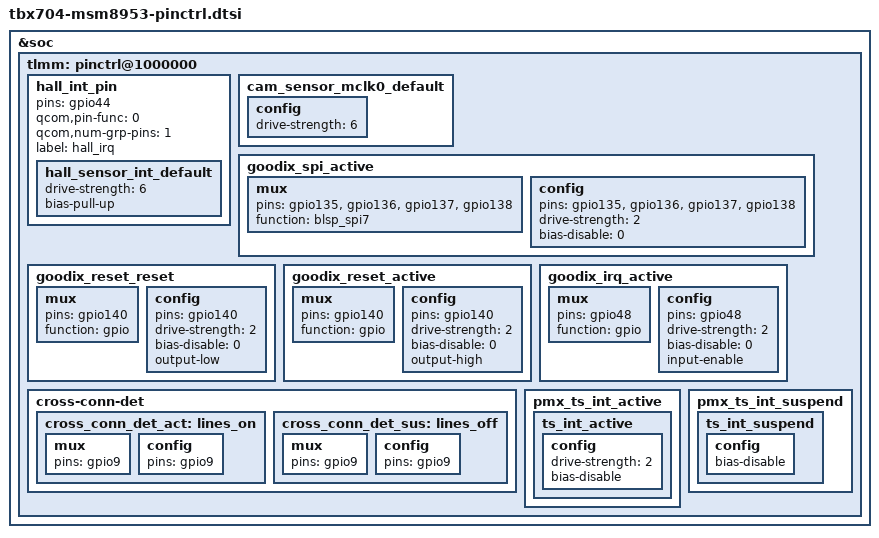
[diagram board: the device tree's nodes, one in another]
/*
 * Copyright (c) 2015-2016, The Linux Foundation. All rights reserved.
 *
 * This program is free software; you can redistribute it and/or modify
 * it under the terms of the GNU General Public License version 2 and
 * only version 2 as published by the Free Software Foundation.
 *
 * This program is distributed in the hope that it will be useful,
 * but WITHOUT ANY WARRANTY; without even the implied warranty of
 * MERCHANTABILITY or FITNESS FOR A PARTICULAR PURPOSE.  See the
 * GNU General Public License for more details.
 */

&soc {
	tlmm: pinctrl@1000000 {
		hall_int_pin {
			pins = "gpio44";
			qcom,pin-func = <0>;
			qcom,num-grp-pins = <1>;
			label = "hall_irq";
			hall_sensor_int_default: hall_sensor_int_default {
				drive-strength = <6>;
				bias-pull-up;
			};
		};
		/*sensors */
		cam_sensor_mclk0_default: cam_sensor_mclk0_default {
			config {
				drive-strength = <6>; /* 6 MA */
			};
		};
		goodix_spi_active: goodix_spi_active{
			mux {
				pins = "gpio135", "gpio136", "gpio137", "gpio138";
				function = "blsp_spi7";
			};
			config {
				pins = "gpio135", "gpio136", "gpio137", "gpio138";
				drive-strength = <2>;
				bias-disable = <0>;
			};
		};
		goodix_reset_reset: goodix_reset_reset{
			mux {
				pins = "gpio140";
				function = "gpio";
			};
			config {
				pins = "gpio140";
				drive-strength = <2>;
				bias-disable = <0>;
				output-low;
			};
		};
		goodix_reset_active: goodix_reset_active{
			mux {
				pins = "gpio140";
				function = "gpio";
			};
			config {
				pins = "gpio140";
				drive-strength = <2>;
				bias-disable = <0>;
				output-high;
			};
		};
		goodix_irq_active: goodix_irq_active {
			mux {
				pins = "gpio48";
				function = "gpio";
			};
			config {
				pins = "gpio48";
				drive-strength = <2>;
				bias-disable = <0>;
				input-enable;
			};
		};
		cross-conn-det {
			cross_conn_det_act: lines_on {
				mux {
					pins = "gpio9";
				};

				config {
					pins = "gpio9";
				};
			};

			cross_conn_det_sus: lines_off {
				mux {
					pins = "gpio9";
				};

				config {
					pins = "gpio9";
				};
			};
		};
		/* add pingrp for touchscreen */
		pmx_ts_int_active {
			ts_int_active: ts_int_active {
				config {
					drive-strength = <2>;
					/delete-property/ bias-pull-up;
					bias-disable;
				};
			};
		};

		pmx_ts_int_suspend {
			ts_int_suspend: ts_int_suspend {
				config {
					/delete-property/ bias-pull-down;
					bias-disable;
				};
			};
		};

	};
};
